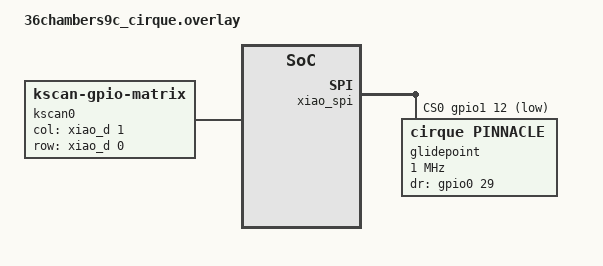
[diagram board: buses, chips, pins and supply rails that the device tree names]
#include "36chambers9c.dtsi" // Notice that the main dtsi files are included in the overlay.
#include <dt-bindings/zmk/input_transform.h>
#include <input/processors.dtsi>

&xiao_spi {
    status = "okay";
    cs-gpios = <&gpio1 12 GPIO_ACTIVE_LOW>; // this is d7
    glidepoint: glidepoint@0 {
        compatible = "cirque,pinnacle";
        reg = <0>;
        spi-max-frequency = <1000000>;
        status = "okay";
        dr-gpios = <&gpio0 29 (GPIO_ACTIVE_HIGH)>; // this is d3
        // sensitivity = "3x";
        // sleep;
        // no-taps;
    };
};

/ {
    glidepoint_listener {
        status = "okay";
        compatible = "zmk,input-listener";
        device = <&glidepoint>;
        // input-processors = <&zip_xy_transform (INPUT_TRANSFORM_XY_SWAP)>;
        input-processors = <&zip_xy_transform (INPUT_TRANSFORM_X_INVERT)>; // swap x and y, invert x and y
        // input-processors = <&zip_xy_scaler 5 2>; //2.5 faster cursor
        // input-processors = <&zip_xy_scaler 3 1>; // 3x faster cursor
        input-processors = <&zip_xy_scaler 4 1>; // 4x faster cursor
        // input-processors = <&zip_temp_layer 8 2000>; // say in layer 8 for 2 seconds
    };
    chosen {
		zmk,kscan = &kscan0;
		zmk,matrix_transform = &default_transform;
	};

// 	default_transform: keymap_transform_0 {
// 		compatible = "zmk,matrix-transform";
// 		columns = <12>;
        
// 		rows = <5>;
// // | SW1  | SW2  | SW3  | SW4  | SW5  |   | SW5  | SW4  | SW3  | SW2  | SW1  |
// // | SW6  | SW7  | SW8  | SW9  | SW10 |   | SW10 | SW9  | SW8  | SW7  | SW6  |
// // | SW11 | SW12 | SW13 | SW14 | SW15 |   | SW15 | SW14 | SW13 | SW12 | SW11 |
// // | SW16 |      |      | SW17 | SW18 |   | SW19 | SW19 | SW18 |      | SW16 |
// // | U3A  | U3CT | U3C  | U3B  | U3D  |   | SW24 | SW23 | SW22 | SW21 | SW20 |
// 		map = <
// RC(0,0) RC(0,1) RC(0,2) RC(0,3) RC(0,4)          RC(0,6) RC(0,7) RC(0,8) RC(0,9) RC(0,10)
// RC(1,0) RC(1,1) RC(1,2) RC(1,3) RC(1,4)          RC(1,6) RC(1,7) RC(1,8) RC(1,9) RC(1,10)
// RC(2,0) RC(2,1) RC(2,2) RC(2,3) RC(2,4)          RC(2,6) RC(2,7) RC(2,8) RC(2,9) RC(2,10)
// RC(3,0)         RC(3,2) RC(3,3) RC(3,4)          RC(3,6) RC(3,7) RC(3,8)         RC(3,10)
// RC(4,0) RC(4,1) RC(4,2) RC(4,3) RC(4,4) RC(4,5)  RC(4,6) RC(4,7) RC(4,8) RC(4,9) RC(4,10) RC(4,11)
// 		>;
// 	};
kscan0: kscan {
        compatible = "zmk,kscan-gpio-matrix";
        diode-direction = "col2row";
    col-gpios
        = <&xiao_d 1 GPIO_ACTIVE_HIGH>  //Col0
    //     , <&xiao_d 9 GPIO_ACTIVE_HIGH>   //Col1
    //     , <&xiao_d 8 GPIO_ACTIVE_HIGH>   //Col2
    //     , <&xiao_d 7 GPIO_ACTIVE_HIGH>   //Col3
    //     , <&xiao_d 5 GPIO_ACTIVE_HIGH> //Col4
    //     , <&xiao_d 6 GPIO_ACTIVE_HIGH> //Col5
        ;
	row-gpios
    	= <&xiao_d 0 (GPIO_ACTIVE_HIGH | GPIO_PULL_DOWN)>//Row0
    //     , <&xiao_d 1 (GPIO_ACTIVE_HIGH | GPIO_PULL_DOWN)>//Row1
    //     , <&xiao_d 2 (GPIO_ACTIVE_HIGH | GPIO_PULL_DOWN)>//Row2
    //     , <&xiao_d 3 (GPIO_ACTIVE_HIGH | GPIO_PULL_DOWN)>//Row3
    //     , <&xiao_d 4 (GPIO_ACTIVE_HIGH | GPIO_PULL_DOWN)>//Row4
        ;
    };
};
// #include <zephyr/dt-bindings/input/input-event-codes.h>
// / {
//     /omit-if-no-ref/ zip_temp_layer: zip_temp_layer {
//         compatible = "zmk,input-processor-temp-layer";
//         #input-processor-cells = <2>;
//         // require-prior-idle-ms = <2000>;
//         excluded-positions = <1 2 3 10 11 12 13 14 20 34>;
//     };
// };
